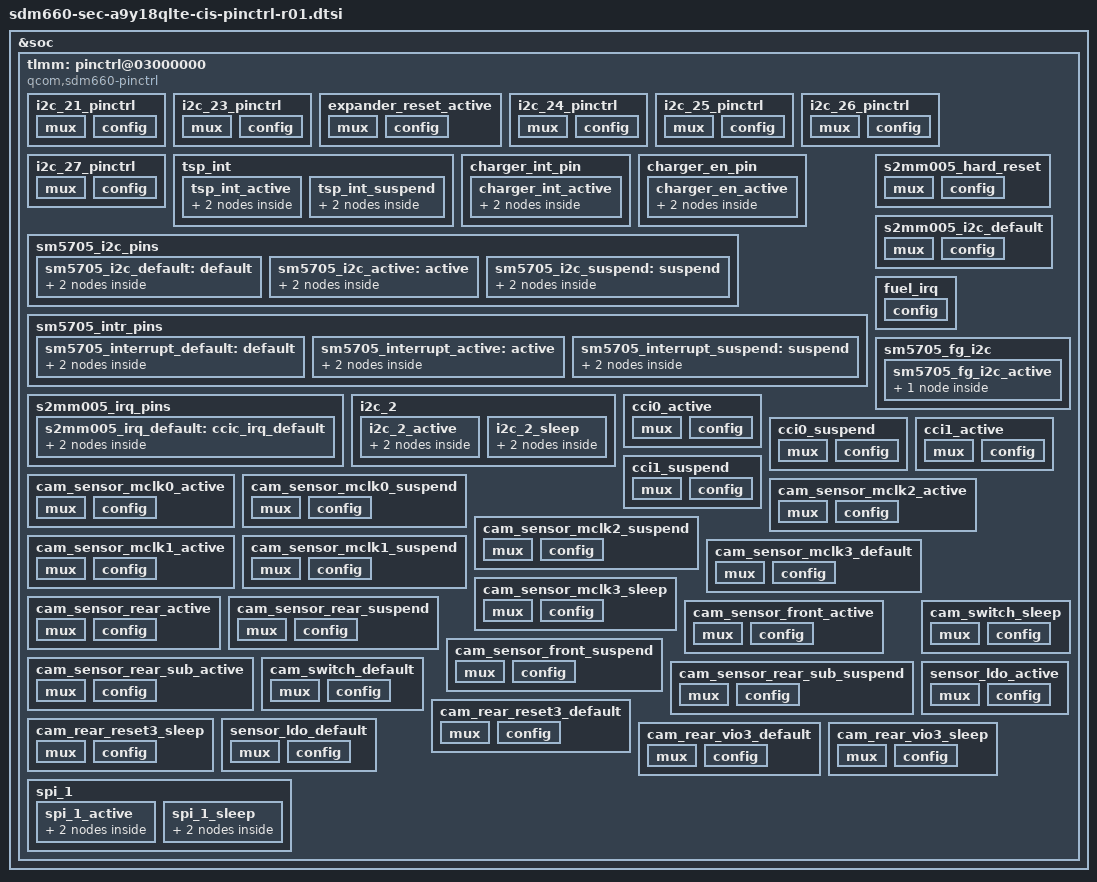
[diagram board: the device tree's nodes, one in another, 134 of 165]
/*
 * Copyright (c) 2017, The Linux Foundation. All rights reserved.
 *
 * This program is free software; you can redistribute it and/or modify
 * it under the terms of the GNU General Public License version 2 and
 * only version 2 as published by the Free Software Foundation.
 *
 * This program is distributed in the hope that it will be useful,
 * but WITHOUT ANY WARRANTY; without even the implied warranty of
 * MERCHANTABILITY or FITNESS FOR A PARTICULAR PURPOSE.  See the
 * GNU General Public License for more details.
 */

#include "sdm660-sec-a9y18qlte-audio-pinctrl.dtsi"

&soc {
	tlmm: pinctrl@03000000 {
		compatible = "qcom,sdm660-pinctrl";
		reg = <0x03000000 0xc00000>;
		interrupts = <0 208 0>;
		gpio-controller;
		#gpio-cells = <2>;
		interrupt-controller;
		#interrupt-cells = <2>;

		/delete-node/tlmm_gpio_key;
		/delete-node/spi_1;

		i2c_21_pinctrl: i2c_21_pinctrl {
			mux {
				pins = "gpio61",	/* GRIP_I2C_SDA_1P8 */
				       "gpio62";	/* GRIP_I2C_SCL_1P8 */
				function = "gpio";
			};
			config {
				pins = "gpio61",	/* GRIP_I2C_SDA_1P8 */
				       "gpio62";	/* GRIP_I2C_SCL_1P8 */
				drive-strength = <2>;
				bias-disable;
			};
		};

		i2c_23_pinctrl: i2c_23_pinctrl {
			mux {
				pins = "gpio52",	/* EXPANDER_I2C_SDA_1P8 */
				       "gpio51";	/* EXPANDER_I2C_SCL_1P8 */
				function = "gpio";
			};
			config {
				pins = "gpio52",	/* EXPANDER_I2C_SDA_1P8 */
				       "gpio51";	/* EXPANDER_I2C_SCL_1P8 */
				drive-strength = <2>;
				bias-disable;
			};
		};

		expander_reset_active: expander_reset_active {
			mux {
				pins = "gpio94";
				function = "gpio";
			};
			config {
				pins = "gpio94";
				drive-strength = <2>;   
				bias-disable;
				output-high;
			};
		};

		i2c_24_pinctrl: i2c_24_pinctrl {
			mux {
				pins = "gpio55",	/* FG_SDA_1P8 */
				       "gpio56";	/* FG_SCL_1P8 */
				function = "gpio";
			};
			config {
				pins = "gpio55",	/* FG_SDA_1P8 */
				       "gpio56";	/* FG_SCL_1P8 */
				drive-strength = <2>;
				bias-disable;
			};
		};

	i2c_25_pinctrl: i2c_25_pinctrl {
			mux {
				pins = "gpio71";	/* PROXY_INT */
				function = "gpio";
			};
			config {
				pins = "gpio71"; /* PROXY_INT */
				drive-strength = <2>;
				bias-disable; /* No PULL */
				output-high;
			};
		};

		i2c_26_pinctrl: i2c_26_pinctrl {
			mux {
				pins = "gpio72",	/* IF_PMIC_SDA_1P8 */
				       "gpio73";	/* IF_PMIC_SCL_1P8 */
				function = "gpio";
			};
			config {
				pins = "gpio72",	/* IF_PMIC_SDA_1P8 */
				       "gpio73";	/* IF_PMIC_SCL_1P8 */
				drive-strength = <2>;
				bias-disable;
			};
		};

		i2c_27_pinctrl: i2c_27_pinctrl {
                        mux {
                                pins = "gpio77",        /* RCAM4_AF_SDA_1P8 */
                                       "gpio76";        /* RCAM4_AF_SCL_1P8 */
                                function = "gpio";
                        };
                        config {
                                pins = "gpio77",        /* RCAM4_AF_SDA_1P8 */
                                       "gpio76";        /* RCAM4_AF_SCL_1P8 */
                                drive-strength = <2>;
                                bias-disable;
                        };
		};

		tsp_int {
			tsp_int_active: tsp_int_active {
				mux {
					pins = "gpio67";
					function = "gpio";
				};

				config {
					pins = "gpio67";
					drive-strength = <2>;
					bias-disable;
					input-enable;
				};
			};

			tsp_int_suspend: tsp_int_suspend {
				mux {
					pins = "gpio67";
					function = "gpio";
				};

				config {
					pins = "gpio67";
					drive-strength = <2>;
					bias-disable;
					input-enable;
				};
			};
		};

		charger_int_pin {
			//qcom,pins = <&gp 69>;
			qcom,num-grp-pins = <1>;
			qcom,pin-func = <0>;
			label = "charger_int_gpio";
			charger_int_active: charger_int_active {
				mux {
					pins = "gpio69";
					function = "gpio";				
				};
				config {
					pins = "gpio69";
					drive-strength = <2>;
					bias-disable;         /* No PULL */
				};
			};
		};

		charger_en_pin {
			//qcom,pins = <&gp 63>;
			qcom,num-grp-pins = <1>;
			qcom,pin-func = <0>;
			label = "charger_en_gpio";
			charger_en_active: charger_en_active {
				mux {
					pins = "gpio63";
					function = "gpio";				
				};
				config {
					pins = "gpio63";
					drive-strength = <2>;
					bias-disable;         /* No PULL */
					output-high;
				};
			};
		};

		/* MUIC - SM5705 */
		sm5705_i2c_pins {
			qcom,num-grp-pins = <2>;
			qcom,pin-func = <0>;
			label = "sm5705_gpio";
			sm5705_i2c_default: default {
				mux {
					pins = "gpio72", "gpio73";
					function = "gpio";
				};
				config {
					pins = "gpio72", "gpio73";
					drive-strength = <2>;
					bias-disable;
				};
			};
			sm5705_i2c_active: active {
				mux {
					pins = "gpio72", "gpio73";
					function = "gpio";
				};
				config {
					pins = "gpio72", "gpio73";
					drive-strength = <2>;
					bias-disable;
				};

			};
			sm5705_i2c_suspend: suspend {
				mux {
					pins = "gpio72", "gpio73";
					function = "gpio";
				};
				config {
					pins = "gpio72", "gpio73";
					drive-strength = <2>;
					bias-disable;
				};
			};
		};

		sm5705_intr_pins {
			qcom,pin-func = <0>;
			label = "sm5705_gpio_int";
			sm5705_interrupt_default: default {
				mux {
					pins = "gpio50";
					function = "gpio";
				};
				config {
					pins = "gpio50";
					drive-strength = <2>;
					bias-disable;
				};
			};
			sm5705_interrupt_active: active {
				mux {
					pins = "gpio50";
					function = "gpio";
				};
				config {
					pins = "gpio50";
					drive-strength = <2>;
					bias-disable;
				};
			};
			sm5705_interrupt_suspend: suspend {
				mux {
					pins = "gpio50";
					function = "gpio";
				};
				config {
					pins = "gpio50";
					drive-strength = <2>;
					bias-disable;
				};
			};
		};
		
		s2mm005_irq_pins {
			//qcom,pins = <&gp 58>;
			qcom,num-grp-pins = <1>;
			qcom,pin-func = <0>;
			label = "s2mm005_irq_default";
			s2mm005_irq_default: ccic_irq_default {
				mux {
					pins = "gpio58";
					function = "gpio";				
				};
				config {
					pins = "gpio58";
					drive-strength = <2>;
					bias-disable;         /* No PULL */
					input-enable;
				};
			};			
		};
		s2mm005_hard_reset: s2mm005_hard_reset {
				mux {
					pins = "gpio20", "gpio21";
					function = "gpio";
				};
				config { 
					pins = "gpio20", "gpio21"; 
					drive-strength = <6>; 
					bias-pull-down;
					output-low;
				}; 
		};

		s2mm005_i2c_default: s2mm005_i2c_default {
				mux {
					pins = "gpio20", "gpio21";
					function = "gpio";
				};
				config { 
					pins = "gpio20", "gpio21"; 
					drive-strength = <6>;
					bias-disable;
				}; 
		};

		fuel_irq: fuel_irq {
			config {
				pins = "gpio42";
				bias-disable;         /* No PULL */
			};
		};

		sm5705_fg_i2c {
			sm5705_fg_i2c_active: sm5705_fg_i2c_active {
				sm5705_fg_i2c {
					pins = "gpio55", "gpio56";
					drive-strength = <2>;
					function = "gpio";
					bias-disable;
					input-enable;
				};
			};
		};

		i2c_2 {
			i2c_2_active: i2c_2_active {
				mux {
					pins = "gpio6", "gpio7";
					function = "blsp_i2c2";
				};

				config {
					pins = "gpio6", "gpio7";
					drive-strength = <2>;
					bias-disable;
					output-low;
				};
			};

			i2c_2_sleep: i2c_2_sleep {
				mux {
					pins = "gpio6", "gpio7";
					function = "gpio";
				};

				config {
					pins = "gpio6", "gpio7";
					drive-strength = <2>;
					/delete-property/ bias-pull-up;
					bias-disable; /* No PULL */
					output-low;
				};
			};
		};

		cci0_active: cci0_active {
			mux {
				/* CLK, DATA */
				pins = "gpio36","gpio37"; // Only 2
				function = "cci_i2c";
			};

			config {
				pins = "gpio36","gpio37";
				bias-disable; /* No PULL */
				drive-strength = <2>; /* 2 MA */
				output-low;
			};
		};

		cci0_suspend: cci0_suspend {
			mux {
				/* CLK, DATA */
				pins = "gpio36","gpio37";
				function = "gpio";
			};

			config {
				pins = "gpio36","gpio37";
				/delete-property/ bias-pull-down;
				bias-disable; /* No PULL */
				drive-strength = <2>; /* 2 MA */
				output-low;
			};
		};

		cci1_active: cci1_active {
			mux {
				/* CLK, DATA */
				pins = "gpio38","gpio39";
				function = "cci_i2c";
			};

			config {
				pins = "gpio38","gpio39";
				bias-disable; /* No PULL */
				drive-strength = <2>; /* 2 MA */
				output-low;
			};
		};

		cci1_suspend: cci1_suspend {
			mux {
				/* CLK, DATA */
				pins = "gpio38","gpio39";
				function = "gpio";
			};


			config {
				pins = "gpio38","gpio39";
				/delete-property/ bias-pull-down;
				bias-disable; /* No PULL */
				drive-strength = <2>; /* 2 MA */
				output-low;
			};
		};

		cam_sensor_mclk0_active: cam_sensor_mclk0_active {
			/* MCLK0 */
			mux {
				/* CLK, DATA */
				pins = "gpio32";
				function = "cam_mclk";
			};

			config {
				pins = "gpio32";
				bias-disable; /* No PULL */
				drive-strength = <4>; /* 4 MA */
			};
		};

		cam_sensor_mclk0_suspend: cam_sensor_mclk0_suspend {
			/* MCLK0 */
			mux {
				/* CLK, DATA */
				pins = "gpio32";
				function = "cam_mclk";
			};

			config {
				pins = "gpio32";
				bias-pull-down; /* PULL DOWN */
				drive-strength = <4>; /* 4 MA */
				output-low;
			};
		};
		
		cam_sensor_mclk2_active: cam_sensor_mclk2_active {
			/* MCLK2 */
			mux {
				/* CLK, DATA */
				pins = "gpio34";
				function = "cam_mclk";
			};

			config {
				pins = "gpio34";
				bias-pull-down; /* PULL DOWN */
				drive-strength = <4>; /* 4 MA */
			};
		};

		cam_sensor_mclk2_suspend: cam_sensor_mclk2_suspend {
			/* MCLK2 */
			mux {
				/* CLK, DATA */
				pins = "gpio34";
				function = "cam_mclk";
			};

			config {
				pins = "gpio34";
				bias-pull-down; /* PULL DOWN */
				drive-strength = <4>; /* 4 MA */
				output-low;
			};
		};

		cam_sensor_mclk1_active: cam_sensor_mclk1_active {
			/* MCLK1 */
			mux {
				/* CLK, DATA */
				pins = "gpio33";
				function = "cam_mclk";
			};

			config {
				pins = "gpio33";
				bias-pull-down; /* PULL DOWN */
				drive-strength = <4>; /* 4 MA */
                                output-low;
			};
		};

		cam_sensor_mclk1_suspend: cam_sensor_mclk1_suspend {
			/* MCLK1 */
			mux {
				/* CLK, DATA */
				pins = "gpio33";
				function = "cam_mclk";
			};

			config {
				pins = "gpio33";
				bias-disable; /* No PULL */
				drive-strength = <4>; /* 4 MA */
				output-low;
			};
		};

		cam_sensor_mclk3_default: cam_sensor_mclk3_default {
			/* MCLK3 */
			mux {
				/* CLK, DATA */
				pins = "gpio35";
				function = "cam_mclk";
			};

			config {
				pins = "gpio35";
				bias-pull-down; /* PULL DOWN */
				drive-strength = <4>; /* 4 MA */
				output-low;
			};
		};

		cam_sensor_mclk3_sleep: cam_sensor_mclk3_sleep {
			/* MCLK3 */
			mux {
				/* CLK, DATA */
				pins = "gpio35";
				function = "cam_mclk";
			};

			config {
				pins = "gpio35";
				bias-disable; /* No PULL */
				drive-strength = <4>; /* 4 MA */
				output-low;
			};
		};
				
		cam_sensor_rear_active: cam_sensor_rear_active {
			/* RESET */
			mux {
				pins = "gpio46";
				function = "gpio";
			};

			config {
				pins = "gpio46";
				bias-disable; /* No PULL */
				drive-strength = <2>; /* 2 MA */
				output-low;
			};
		};

		cam_sensor_rear_suspend: cam_sensor_rear_suspend {
			/* RESET */
			mux {
				pins = "gpio46";
				function = "gpio";
			};

			config {
				pins = "gpio46";
				bias-disable; /* No PULL */
				drive-strength = <2>; /* 2 MA */
			};
		};

		cam_sensor_front_active: cam_sensor_front_active {
			/* RESET*/
			mux {
				pins = "gpio47";
				function = "gpio";
			};

			config {
				pins = "gpio47";
				bias-disable; /* No PULL */
				drive-strength = <2>; /* 2 MA */
				output-low;
			};
		};

		cam_sensor_front_suspend: cam_sensor_front_suspend {
			/* RESET */
			mux {
				pins = "gpio47";
				function = "gpio";
			};
			config {
				pins = "gpio47";
				bias-disable; /* No PULL */
				drive-strength = <2>; /* 2 MA */
			};
		};
		
		cam_sensor_rear_sub_active: cam_sensor_rear_sub_active {
			/* RESET */
			mux {
				pins = "gpio48";
				function = "gpio";
			};

			config {
				pins = "gpio48";
				bias-disable; /* No PULL */
				drive-strength = <2>; /* 2 MA */
				output-low;
			};
		};

		cam_sensor_rear_sub_suspend: cam_sensor_rear_sub_suspend {
			/* RESET */
			mux {
				pins = "gpio48";
				function = "gpio";
			};

			config {
				pins = "gpio48";
				bias-disable; /* No PULL */
				drive-strength = <2>; /* 2 MA */
			};
		};

	        cam_switch_default: cam_switch_default {
			/* RESET, STANDBY */
			mux {
				pins = "gpio86";
				function = "gpio";
			};

			config {
				pins = "gpio86";
				bias-pull-down; /* PULL DOWN */
				drive-strength = <2>; /* 2 MA */
				output-low;
			};
	        };

	        cam_switch_sleep: cam_switch_sleep {
			/* RESET, STANDBY */
			mux {
				pins = "gpio86";
				function = "gpio";
			};

			config {
				pins = "gpio86";
				bias-pull-down; /* PULL DOWN */
				drive-strength = <2>; /* 2 MA */
				output-low;
			};
		};

		cam_rear_reset3_default: cam_rear_reset3_default {
			/* RESET */
			mux {
				pins = "gpio96";
				function = "gpio";
			};

			config {
				pins = "gpio96";
				bias-pull-down; /* PULL DOWN */
				drive-strength = <2>; /* 2 MA */
				output-low;
			};
		};

		cam_rear_reset3_sleep: cam_rear_reset3_sleep {
			/* RESET */
			mux {
				pins = "gpio96";
				function = "gpio";
			};

			config {
				pins = "gpio96";
				bias-pull-down; /* PULL DOWN */
				drive-strength = <2>; /* 2 MA */
                                output-low;
			};
		};

		sensor_ldo_default: sensor_ldo_default {
			mux {
				pins = "gpio113";
				function = "gpio";
			};

			config {
				pins = "gpio113";
				bias-disable; /* No PULL */
				drive-strength = <2>; /* 2 MA */
				output-low;
			};
		};

		sensor_ldo_active: sensor_ldo_active {
			mux {
				pins = "gpio113";
				function = "gpio";
			};

			config {
				pins = "gpio113";
				bias-disable; /* No PULL */
				drive-strength = <2>; /* 2 MA */
				output-high;
			};
		};

		cam_rear_vio3_default: cam_rear_vio3_default {
			/* VIO, VANA, VDIG */
			mux {
				pins = "gpio12";
				function = "gpio";
			};

			config {
				pins = "gpio12";
				bias-disable; /* No PULL */
				drive-strength = <2>; /* 2 MA */
				output-low;
			};
		};

		cam_rear_vio3_sleep: cam_rear_vio3_sleep {
			/* VIO, VANA, VDIG */
			mux {
				pins = "gpio12";
				function = "gpio";
			};

			config {
				pins = "gpio12";
				bias-disable; /* No PULL */
				drive-strength = <2>; /* 2 MA */
				output-low;
			};
		};

		spi_1 {
			spi_1_active: spi_1_active {
			      mux {
				      pins = "gpio0", "gpio1",
					   "gpio2", "gpio3";
				      function = "blsp_spi1";
			      };
			      config {
				      pins = "gpio0", "gpio1",
					   "gpio2", "gpio3";
				      drive-strength = <6>;
				      bias-disable;
			      };
		      };

			spi_1_sleep: spi_1_sleep {
			     mux {
				     pins = "gpio0", "gpio1",
					  "gpio2", "gpio3";
				     function = "gpio";
			     };

			     config {
				     pins = "gpio0", "gpio1",
					  "gpio2", "gpio3";
				     drive-strength = <6>;
				     bias-pulll-down;
				     output-low;
			     };
		     };
	      };
	};
};
